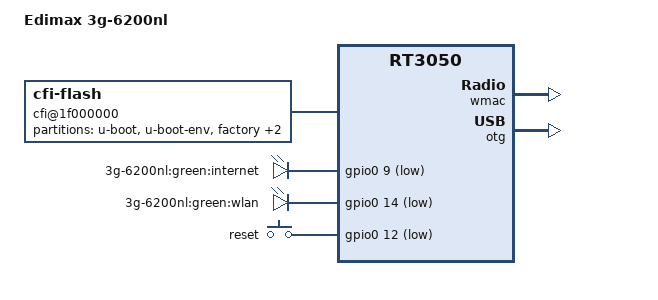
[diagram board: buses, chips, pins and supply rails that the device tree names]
/dts-v1/;

#include "rt3050.dtsi"

#include <dt-bindings/gpio/gpio.h>
#include <dt-bindings/input/input.h>

/ {
	compatible = "edimax,3g-6200nl", "ralink,rt3050-soc";
	model = "Edimax 3g-6200nl";

	aliases {
		led-boot = &led_internet;
		led-failsafe = &led_internet;
		led-running = &led_internet;
		led-upgrade = &led_internet;
	};

	cfi@1f000000 {
		compatible = "cfi-flash";
		reg = <0x1f000000 0x800000>;
		bank-width = <2>;
		device-width = <2>;

		partitions {
			compatible = "fixed-partitions";
			#address-cells = <1>;
			#size-cells = <1>;

			partition@0 {
				label = "u-boot";
				reg = <0x0 0x30000>;
				read-only;
			};

			partition@30000 {
				label = "u-boot-env";
				reg = <0x30000 0x10000>;
				read-only;
			};

			factory: partition@40000 {
				label = "factory";
				reg = <0x40000 0x10000>;
				read-only;
			};

			partition@3e0000 {
				label = "cimage";
				reg = <0x3e0000 0x20000>;
				read-only;
			};

			partition@50000 {
				compatible = "edimax,uimage";
				label = "firmware";
				reg = <0x50000 0x390000>;
			};
		};
	};

	leds {
		compatible = "gpio-leds";

		led_internet: internet {
			label = "3g-6200nl:green:internet";
			gpios = <&gpio0 9 GPIO_ACTIVE_LOW>;
		};

		wlan {
			label = "3g-6200nl:green:wlan";
			gpios = <&gpio0 14 GPIO_ACTIVE_LOW>;
		};
	};

	keys {
		compatible = "gpio-keys-polled";
		poll-interval = <20>;

		reset {
			label = "reset";
			gpios = <&gpio0 12 GPIO_ACTIVE_LOW>;
			linux,code = <KEY_RESTART>;
		};
	};
};

&pinctrl {
	state_default: pinctrl0 {
		gpio {
			ralink,group = "spi", "i2c", "jtag", "rgmii", "mdio", "uartf";
			ralink,function = "gpio";
		};
	};
};

&ethernet {
	mtd-mac-address = <&factory 0x4>;
};

&esw {
	mediatek,portdisable = <0x37>;
};

&wmac {
	ralink,mtd-eeprom = <&factory 0>;
};

&otg {
	status = "okay";
};
